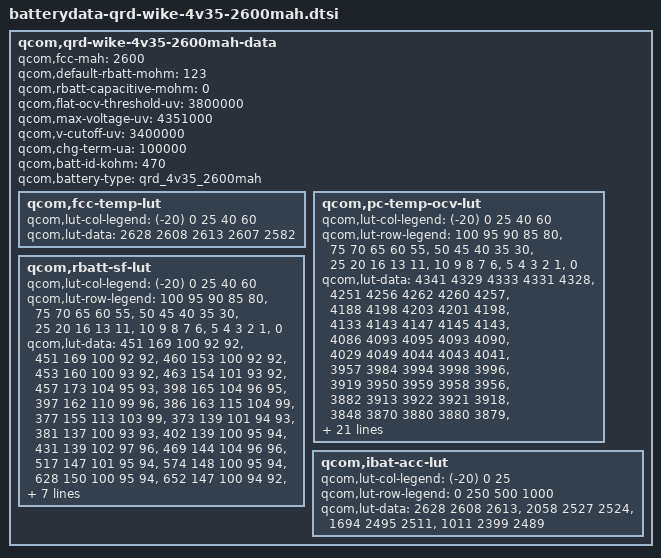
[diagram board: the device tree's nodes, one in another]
/* 
    ADD for L8150 project, wike battery cell
 */
qcom,qrd-wike-4v35-2600mah-data {
	qcom,fcc-mah = <2600>;
	qcom,default-rbatt-mohm = <123>;
	qcom,rbatt-capacitive-mohm = <0>;
	qcom,flat-ocv-threshold-uv = <3800000>;
	qcom,max-voltage-uv = <4351000>;
	qcom,v-cutoff-uv = <3400000>;
	qcom,chg-term-ua = <100000>;
	qcom,batt-id-kohm = <470>;
	qcom,battery-type = "qrd_4v35_2600mah";

	qcom,fcc-temp-lut {
		qcom,lut-col-legend = <(-20) 0 25 40 60>;
		qcom,lut-data = <2628 2608 2613 2607 2582>;
    };
	qcom,pc-temp-ocv-lut {
		qcom,lut-col-legend = <(-20) 0 25 40 60>;
		qcom,lut-row-legend = <100 95 90 85 80>,
				<75 70 65 60 55>,
				<50 45 40 35 30>,
				<25 20 16 13 11>,
				<10 9 8 7 6>,
				<5 4 3 2 1>,
				<0>;
		qcom,lut-data = <4341 4329 4333 4331 4328>,
				<4251 4256 4262 4260 4257>,
				<4188 4198 4203 4201 4198>,
				<4133 4143 4147 4145 4143>,
				<4086 4093 4095 4093 4090>,
				<4029 4049 4044 4043 4041>,
				<3957 3984 3994 3998 3996>,
				<3919 3950 3959 3958 3956>,
				<3882 3913 3922 3921 3918>,
				<3848 3870 3880 3880 3879>,
				<3820 3837 3841 3840 3839>,
				<3801 3813 3816 3815 3814>,
				<3788 3795 3797 3796 3795>,
				<3778 3781 3783 3781 3779>,
				<3767 3772 3769 3765 3759>,
				<3752 3761 3753 3743 3731>,
				<3733 3744 3734 3722 3709>,
				<3712 3721 3713 3702 3688>,
				<3697 3696 3688 3678 3665>,
				<3688 3689 3681 3671 3659>,
				<3684 3687 3680 3670 3658>,
				<3680 3686 3679 3669 3658>,
				<3675 3684 3677 3668 3656>,
				<3669 3681 3675 3666 3654>,
				<3658 3676 3669 3660 3648>,
				<3637 3660 3651 3640 3621>,
				<3598 3614 3611 3599 3577>,
				<3539 3556 3552 3534 3517>,
				<3453 3470 3471 3451 3436>,
				<3317 3332 3344 3319 3309>,
				<3000 3000 3000 3000 3000>;
    };
	qcom,rbatt-sf-lut {
		qcom,lut-col-legend = <(-20) 0 25 40 60>;
		qcom,lut-row-legend = <100 95 90 85 80>,
				<75 70 65 60 55>,
				<50 45 40 35 30>,
				<25 20 16 13 11>,
				<10 9 8 7 6>,
				<5 4 3 2 1>,
				<0>;
		qcom,lut-data = <451 169 100 92 92>,
				<451 169 100 92 92>,
				<460 153 100 92 92>,
				<453 160 100 93 92>,
				<463 154 101 93 92>,
				<457 173 104 95 93>,
				<398 165 104 96 95>,
				<397 162 110 99 96>,
				<386 163 115 104 99>,
				<377 155 113 103 99>,
				<373 139 101 94 93>,
				<381 137 100 93 93>,
				<402 139 100 95 94>,
				<431 139 102 97 96>,
				<469 144 104 96 96>,
				<517 147 101 95 94>,
				<574 148 100 95 94>,
				<628 150 100 95 94>,
				<652 147 100 94 92>,
				<708 149 100 93 92>,
				<743 152 101 95 94>,
				<786 158 102 96 95>,
				<832 161 104 98 99>,
				<888 170 108 101 102>,
				<946 178 109 104 104>,
				<1006 182 109 98 97>,
				<1082 184 106 98 97>,
				<1198 204 109 100 98>,
				<1345 212 117 106 104>,
				<1678 464 142 139 126>,
				<253164 243266 187826 163820 79443>;
    };

	qcom,ibat-acc-lut {
		qcom,lut-col-legend = <(-20) 0 25>;
		qcom,lut-row-legend = <0 250 500 1000>;
		qcom,lut-data = <2628 2608 2613>,
				<2058 2527 2524>,
				<1694 2495 2511>,
				<1011 2399 2489>;
	};

};
